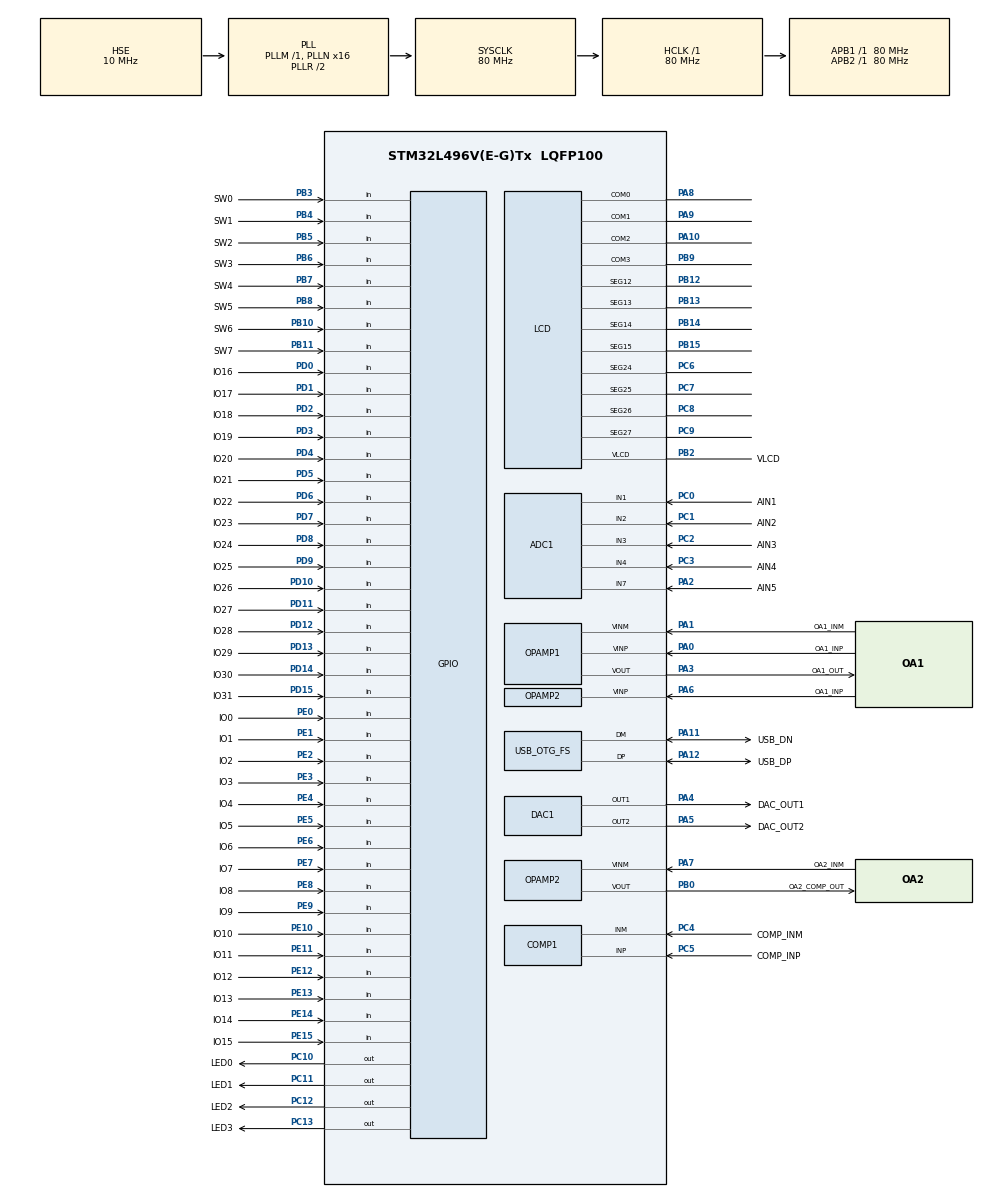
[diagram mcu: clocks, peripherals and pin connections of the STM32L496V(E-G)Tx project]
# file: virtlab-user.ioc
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ADC1.Channel-0\#ChannelRegularConversion=ADC_CHANNEL_1
ADC1.ClockPrescaler=ADC_CLOCK_ASYNC_DIV2
ADC1.NbrOfConversionFlag=1
ADC1.OffsetNumber-0\#ChannelRegularConversion=ADC_OFFSET_NONE
ADC1.Rank-0\#ChannelRegularConversion=1
ADC1.SamplingTime-0\#ChannelRegularConversion=ADC_SAMPLETIME_2CYCLES_5
ADC1.master=1
ADC3.Channel-1\#ChannelRegularConversion=ADC_CHANNEL_14
ADC3.ClockPrescaler=ADC_CLOCK_ASYNC_DIV2
ADC3.NbrOfConversionFlag=1
ADC3.OffsetNumber-1\#ChannelRegularConversion=ADC_OFFSET_NONE
ADC3.Rank-1\#ChannelRegularConversion=1
ADC3.SamplingTime-1\#ChannelRegularConversion=ADC_SAMPLETIME_2CYCLES_5
DAC1.DAC_Channel-DAC_OUT2_ExtAndInt=DAC_CHANNEL_2
DAC1.DAC_UserTrimming-DAC_OUT1_ExtAndInt=DAC_TRIMMING_FACTORY
FREERTOS.BinarySemaphores01=myBinarySem,Dynamic,NULL
FREERTOS.Mutexes01=myMutex,Dynamic,NULL
FREERTOS.Tasks01=defaultTask,24,1024,StartDefaultTask,As weak,NULL,Static,defaultTaskBuffer,defaultTaskControlBlock;usbTxTask,24,1024,StartUsbTxTask,As external,NULL,Static,usbTxTaskBuffer,usbTxTaskControlBlock;myTask1,24,128,StartTask1,Default,NULL,Dynamic,NULL,NULL;myTask2,24,128,StartTask2,Default,NULL,Dynamic,NULL,NULL;myTask3,24,128,StartTask3,Default,NULL,Dynamic,NULL,NULL
FREERTOS.configUSE_NEWLIB_REENTRANT=1
Mcu.Family=STM32L4
Mcu.Name=STM32L496V(E-G)Tx
Mcu.Package=LQFP100
NVIC.OTG_FS_IRQn=true\:5\:0\:false\:false\:true\:false\:false\:true\:true
NVIC.PriorityGroup=NVIC_PRIORITYGROUP_4
NVIC.TIM1_UP_TIM16_IRQn=true\:0\:0\:false\:false\:true\:false\:false\:true\:true
NVIC.TimeBase=TIM1_UP_TIM16_IRQn
NVIC.TimeBaseIP=TIM16
OPAMP2.PowerSupplyRange=OPAMP_POWERSUPPLY_LOW
PA0.GPIO_Label=OA1_INP
PA0.Mode=PGA Connected
PA0.Signal=OPAMP1_VINP
PA1.GPIO_Label=OA1_INM
PA1.Mode=PGA Connected
PA1.Signal=OPAMP1_VINM
PA10.Mode=1/4 Duty Cycle
PA10.Signal=LCD_COM2
PA11.GPIO_Label=USB_DN
PA11.Mode=Device_Only
PA11.Signal=USB_OTG_FS_DM
PA12.GPIO_Label=USB_DP
PA12.Mode=Device_Only
PA12.Signal=USB_OTG_FS_DP
PA13\ (JTMS/SWDIO).GPIO_Label=SWDIO
PA13\ (JTMS/SWDIO).Mode=Serial_Wire
PA13\ (JTMS/SWDIO).Signal=SYS_JTMS-SWDIO
PA14\ (JTCK/SWCLK).GPIO_Label=SWCLK
PA14\ (JTCK/SWCLK).Mode=Serial_Wire
PA14\ (JTCK/SWCLK).Signal=SYS_JTCK-SWCLK
PA2.GPIO_Label=AIN5
PA2.Signal=ADCx_IN7
PA3.GPIO_Label=OA1_OUT
PA3.Mode=PGA Connected
PA3.Signal=OPAMP1_VOUT
PA4.GPIO_Label=DAC_OUT1
PA4.Signal=COMP_DAC11_group
PA5.GPIO_Label=DAC_OUT2
PA5.Signal=COMP_DAC12_group
PA6.GPIO_Label=OA1_INP
PA6.Mode=PGA Connected
PA6.Signal=OPAMP2_VINP
PA7.GPIO_Label=OA2_INM
PA7.Mode=PGA Connected
PA7.Signal=OPAMP2_VINM
PA8.Mode=1/4 Duty Cycle
PA8.Signal=LCD_COM0
PA9.Mode=1/4 Duty Cycle
PA9.Signal=LCD_COM1
PB0.GPIO_Label=OA2_COMP_OUT
PB0.Mode=PGA Connected
PB0.Signal=OPAMP2_VOUT
PB10.GPIO_Label=SW6
PB10.GPIO_PuPd=GPIO_PULLDOWN
PB10.Signal=GPIO_Input
PB11.GPIO_Label=SW7
PB11.GPIO_PuPd=GPIO_PULLDOWN
PB11.Signal=GPIO_Input
PB12.Mode=SEG12
PB12.Signal=LCD_SEG12
PB13.Mode=SEG13
PB13.Signal=LCD_SEG13
PB14.Mode=SEG14
PB14.Signal=LCD_SEG14
PB15.Mode=SEG15
PB15.Signal=LCD_SEG15
PB2.GPIO_Label=VLCD
PB2.Mode=1/4 Duty Cycle
PB2.Signal=LCD_VLCD
PB3\ (JTDO/TRACESWO).GPIO_Label=SW0
PB3\ (JTDO/TRACESWO).GPIO_PuPd=GPIO_PULLDOWN
PB3\ (JTDO/TRACESWO).Signal=GPIO_Input
PB4\ (NJTRST).GPIO_Label=SW1
PB4\ (NJTRST).GPIO_PuPd=GPIO_PULLDOWN
PB4\ (NJTRST).Signal=GPIO_Input
PB5.GPIO_Label=SW2
PB5.GPIO_PuPd=GPIO_PULLDOWN
PB5.Signal=GPIO_Input
PB6.GPIO_Label=SW3
PB6.GPIO_PuPd=GPIO_PULLDOWN
PB6.Signal=GPIO_Input
PB7.GPIO_Label=SW4
PB7.GPIO_PuPd=GPIO_PULLDOWN
PB7.Signal=GPIO_Input
PB8.GPIO_Label=SW5
PB8.GPIO_PuPd=GPIO_PULLDOWN
PB8.Signal=GPIO_Input
PB9.Mode=1/4 Duty Cycle
PB9.Signal=LCD_COM3
PC0.GPIO_Label=AIN1
PC0.Signal=ADCx_IN1
PC1.GPIO_Label=AIN2
PC1.Signal=ADCx_IN2
PC10.GPIO_Label=LED0
PC10.Signal=GPIO_Output
PC11.GPIO_Label=LED1
PC11.Signal=GPIO_Output
PC12.GPIO_Label=LED2
PC12.Signal=GPIO_Output
PC13.GPIO_Label=LED3
PC13.Signal=GPIO_Output
PC14-OSC32_IN\ (PC14).GPIO_Label=OSC32_IN
PC14-OSC32_IN\ (PC14).Mode=LSE-External-Clock-Source
PC14-OSC32_IN\ (PC14).Signal=RCC_OSC32_IN
PC2.GPIO_Label=AIN3
PC2.Signal=ADCx_IN3
PC3.GPIO_Label=AIN4
PC3.Signal=ADCx_IN4
PC4.GPIO_Label=COMP_INM
PC4.Mode=INM
PC4.Signal=COMP1_INM
PC5.GPIO_Label=COMP_INP
PC5.Mode=INP
PC5.Signal=COMP1_INP
PC6.Mode=SEG24
PC6.Signal=LCD_SEG24
PC7.Mode=SEG25
PC7.Signal=LCD_SEG25
PC8.Mode=SEG26
PC8.Signal=LCD_SEG26
PC9.Mode=SEG27
PC9.Signal=LCD_SEG27
PD0.GPIO_Label=IO16
PD0.Signal=GPIO_Input
PD1.GPIO_Label=IO17
PD1.Signal=GPIO_Input
PD10.GPIO_Label=IO26
PD10.Signal=GPIO_Input
PD11.GPIO_Label=IO27
PD11.Signal=GPIO_Input
PD12.GPIO_Label=IO28
PD12.Signal=GPIO_Input
PD13.GPIO_Label=IO29
PD13.Signal=GPIO_Input
PD14.GPIO_Label=IO30
PD14.Signal=GPIO_Input
PD15.GPIO_Label=IO31
PD15.Signal=GPIO_Input
PD2.GPIO_Label=IO18
PD2.Signal=GPIO_Input
PD3.GPIO_Label=IO19
PD3.Signal=GPIO_Input
PD4.GPIO_Label=IO20
PD4.Signal=GPIO_Input
PD5.GPIO_Label=IO21
PD5.Signal=GPIO_Input
PD6.GPIO_Label=IO22
PD6.Signal=GPIO_Input
PD7.GPIO_Label=IO23
PD7.Signal=GPIO_Input
PD8.GPIO_Label=IO24
PD8.Signal=GPIO_Input
PD9.GPIO_Label=IO25
PD9.Signal=GPIO_Input
PE0.GPIO_Label=IO0
PE0.Signal=GPIO_Input
PE1.GPIO_Label=IO1
PE1.Signal=GPIO_Input
PE10.GPIO_Label=IO10
PE10.Signal=GPIO_Input
PE11.GPIO_Label=IO11
PE11.Signal=GPIO_Input
PE12.GPIO_Label=IO12
PE12.Signal=GPIO_Input
PE13.GPIO_Label=IO13
PE13.Signal=GPIO_Input
PE14.GPIO_Label=IO14
PE14.Signal=GPIO_Input
PE15.GPIO_Label=IO15
PE15.GPIO_PuPd=GPIO_PULLUP
PE15.Signal=GPIO_Input
PE2.GPIO_Label=IO2
PE2.Signal=GPIO_Input
PE3.GPIO_Label=IO3
PE3.Signal=GPIO_Input
PE4.GPIO_Label=IO4
PE4.Signal=GPIO_Input
PE5.GPIO_Label=IO5
PE5.Signal=GPIO_Input
PE6.GPIO_Label=IO6
PE6.Signal=GPIO_Input
PE7.GPIO_Label=IO7
PE7.Signal=GPIO_Input
PE8.GPIO_Label=IO8
PE8.Signal=GPIO_Input
PE9.GPIO_Label=IO9
PE9.Signal=GPIO_Input
PH0-OSC_IN\ (PH0).GPIO_Label=OSC_IN
PH0-OSC_IN\ (PH0).Mode=HSE-External-Clock-Source
PH0-OSC_IN\ (PH0).Signal=RCC_OSC_IN
ProjectManager.HeapSize=0x200
ProjectManager.StackSize=0x400
ProjectManager.TargetToolchain=STM32CubeIDE
RCC.ADCFreq_Value=80000000
RCC.AHBFreq_Value=80000000
RCC.APB1Freq_Value=80000000
RCC.APB1TimFreq_Value=80000000
RCC.APB2Freq_Value=80000000
RCC.APB2TimFreq_Value=80000000
RCC.CK48CLockSelection=RCC_USBCLKSOURCE_HSI48
RCC.CortexFreq_Value=80000000
RCC.HCLKFreq_Value=80000000
RCC.HSE_VALUE=10000000
RCC.HSI48_VALUE=48000000
RCC.HSI_VALUE=16000000
RCC.LSCOSource1=RCC_LSCOSOURCE_LSE
RCC.LSE_VALUE=32768
RCC.MSI_VALUE=4000000
RCC.PLLN=16
RCC.PLLSAI1N=32
RCC.PLLSAI1Q=RCC_PLLQ_DIV4
RCC.PLLSAI1R=RCC_PLLR_DIV4
RCC.PLLSAI2N=10
RCC.PLLSourceVirtual=RCC_PLLSOURCE_HSE
RCC.RCC_MCODiv=RCC_MCODIV_8
RCC.RTCClockSelection=RCC_RTCCLKSOURCE_LSE
RCC.SYSCLKFreq_VALUE=80000000
RCC.SYSCLKSource=RCC_SYSCLKSOURCE_PLLCLK
RCC.USBFreq_Value=48000000
RCC.VCOOutputFreq_Value=160000000
SH.ADCx_IN1.0=ADC1_IN1,IN1-Single-Ended
SH.ADCx_IN2.0=ADC1_IN2,IN2-Single-Ended
SH.ADCx_IN3.0=ADC1_IN3,IN3-Single-Ended
SH.ADCx_IN4.0=ADC1_IN4,IN4-Single-Ended
SH.ADCx_IN7.0=ADC1_IN7,IN7-Single-Ended
SH.COMP_DAC11_group.0=DAC1_OUT1,DAC_OUT1_ExtAndInt
SH.COMP_DAC12_group.0=DAC1_OUT2,DAC_OUT2_ExtAndInt
SYS.VoltageScaling=SYSCFG_VREFBUF_VOLTAGE_SCALE0
USB_DEVICE.CLASS_NAME_FS=CDC
USB_DEVICE.MANUFACTURER_STRING=MRR
USB_DEVICE.PID_CDC_FS=0x5740
USB_DEVICE.PRODUCT_STRING_CDC_FS=VL User ComPort
USB_DEVICE.USBD_LPM_ENABLED=0
USB_DEVICE.USBD_SELF_POWERED=0
USB_DEVICE.VID=0x483
USB_DEVICE.VirtualMode=Cdc
USB_DEVICE.VirtualModeFS=Cdc_FS
USB_OTG_FS.VirtualMode=Device_Only
VP_ADC1_OPAMP1_OUT.Mode=IN8-OPAMP1-Single-Ended
VP_ADC1_OPAMP2_OUT.Mode=IN15-OPAMP2-Single-Ended
VP_ADC3_VS_DAC1_OUT1_L4.Mode=IN-DAC1-OUT1
VP_ADC3_VS_DAC1_OUT2_L4.Mode=IN-DAC1-OUT2
VP_FREERTOS_VS_CMSIS_V2.Mode=CMSIS_V2
VP_SYS_VS_tim16.Mode=TIM16
VP_USB_DEVICE_VS_USB_DEVICE_CDC_FS.Mode=CDC_FS
VREF+.Mode=InternalMode
VREF+.Signal=VREFBUF_OUT
board=custom

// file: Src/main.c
/* USER CODE BEGIN Header */
/**
  ******************************************************************************
  * @file           : main.c
  * @brief          : Main program body
  ******************************************************************************
  * @attention
  *
  * <h2><center>&copy; Copyright (c) 2020 STMicroelectronics.
  * All rights reserved.</center></h2>
  *
  * This software component is licensed by ST under Ultimate Liberty license
  * SLA0044, the "License"; You may not use this file except in compliance with
  * the License. You may obtain a copy of the License at:
  *                             www.st.com/SLA0044
  *
  ******************************************************************************
  */
/* USER CODE END Header */
#include "main.h"
#include "cmsis_os.h"
#include "usb_device.h"

/* USER CODE BEGIN Includes */
#include "usbserial.h"
/* USER CODE END Includes */

typedef StaticTask_t osStaticThreadDef_t;

ADC_HandleTypeDef hadc1;
ADC_HandleTypeDef hadc3;

COMP_HandleTypeDef hcomp1;

DAC_HandleTypeDef hdac1;

LCD_HandleTypeDef hlcd;

OPAMP_HandleTypeDef hopamp1;
OPAMP_HandleTypeDef hopamp2;

/* Definitions for defaultTask */
osThreadId_t defaultTaskHandle;
uint32_t defaultTaskBuffer[ 1024 ];
osStaticThreadDef_t defaultTaskControlBlock;
const osThreadAttr_t defaultTask_attributes = {
  .name = "defaultTask",
  .cb_mem = &defaultTaskControlBlock,
  .cb_size = sizeof(defaultTaskControlBlock),
  .stack_mem = &defaultTaskBuffer[0],
  .stack_size = sizeof(defaultTaskBuffer),
  .priority = (osPriority_t) osPriorityNormal,
};
/* Definitions for usbTxTask */
osThreadId_t usbTxTaskHandle;
uint32_t usbTxTaskBuffer[ 1024 ];
osStaticThreadDef_t usbTxTaskControlBlock;
const osThreadAttr_t usbTxTask_attributes = {
  .name = "usbTxTask",
  .cb_mem = &usbTxTaskControlBlock,
  .cb_size = sizeof(usbTxTaskControlBlock),
  .stack_mem = &usbTxTaskBuffer[0],
  .stack_size = sizeof(usbTxTaskBuffer),
  .priority = (osPriority_t) osPriorityNormal,
};
/* Definitions for myTask1 */
osThreadId_t myTask1Handle;
const osThreadAttr_t myTask1_attributes = {
  .name = "myTask1",
  .stack_size = 128 * 4,
  .priority = (osPriority_t) osPriorityNormal,
};
/* Definitions for myTask2 */
osThreadId_t myTask2Handle;
const osThreadAttr_t myTask2_attributes = {
  .name = "myTask2",
  .stack_size = 128 * 4,
  .priority = (osPriority_t) osPriorityNormal,
};
/* Definitions for myTask3 */
osThreadId_t myTask3Handle;
const osThreadAttr_t myTask3_attributes = {
  .name = "myTask3",
  .stack_size = 128 * 4,
  .priority = (osPriority_t) osPriorityNormal,
};
/* Definitions for myMutex */
osMutexId_t myMutexHandle;
const osMutexAttr_t myMutex_attributes = {
  .name = "myMutex"
};
/* Definitions for myBinarySem */
osSemaphoreId_t myBinarySemHandle;
const osSemaphoreAttr_t myBinarySem_attributes = {
  .name = "myBinarySem"
};

void SystemClock_Config(void);
void PeriphCommonClock_Config(void);
static void MX_GPIO_Init(void);
static void MX_DAC1_Init(void);
static void MX_OPAMP1_Init(void);
static void MX_OPAMP2_Init(void);
static void MX_ADC1_Init(void);
static void MX_ADC3_Init(void);
static void MX_COMP1_Init(void);
static void MX_LCD_Init(void);
void StartDefaultTask(void *argument);
extern void StartUsbTxTask(void *argument);
void StartTask1(void *argument);
void StartTask2(void *argument);
void StartTask3(void *argument);

int main(void)
{

  /* MCU Configuration--------------------------------------------------------*/

  /* Reset of all peripherals, Initializes the Flash interface and the Systick. */
  HAL_Init();

  /* Configure the system clock */
  SystemClock_Config();

/* Configure the peripherals common clocks */
  PeriphCommonClock_Config();

  /* Initialize all configured peripherals */
  MX_GPIO_Init();
  MX_DAC1_Init();
  MX_OPAMP1_Init();
  MX_OPAMP2_Init();
  MX_ADC1_Init();
  MX_ADC3_Init();
  MX_COMP1_Init();
  MX_LCD_Init();

  /* Init scheduler */
  osKernelInitialize();
  /* Create the mutex(es) */
  /* creation of myMutex */
  myMutexHandle = osMutexNew(&myMutex_attributes);

  /* Create the semaphores(s) */
  /* creation of myBinarySem */
  myBinarySemHandle = osSemaphoreNew(1, 1, &myBinarySem_attributes);

  /* Create the thread(s) */
  /* creation of defaultTask */
  defaultTaskHandle = osThreadNew(StartDefaultTask, NULL, &defaultTask_attributes);

  /* creation of usbTxTask */
  usbTxTaskHandle = osThreadNew(StartUsbTxTask, NULL, &usbTxTask_attributes);

  /* creation of myTask1 */
  myTask1Handle = osThreadNew(StartTask1, NULL, &myTask1_attributes);

  /* creation of myTask2 */
  myTask2Handle = osThreadNew(StartTask2, NULL, &myTask2_attributes);

  /* creation of myTask3 */
  myTask3Handle = osThreadNew(StartTask3, NULL, &myTask3_attributes);

  /* Start scheduler */
  osKernelStart();

  /* We should never get here as control is now taken by the scheduler */
  /* Infinite loop */
  while (1)
  {

  }
}

void SystemClock_Config(void)
{
  RCC_OscInitTypeDef RCC_OscInitStruct = {0};
  RCC_ClkInitTypeDef RCC_ClkInitStruct = {0};

  /** Configure the main internal regulator output voltage
  */
  if (HAL_PWREx_ControlVoltageScaling(PWR_REGULATOR_VOLTAGE_SCALE1) != HAL_OK)
  {
    Error_Handler();
  }

  /** Initializes the RCC Oscillators according to the specified parameters
  * in the RCC_OscInitTypeDef structure.
  */
  RCC_OscInitStruct.OscillatorType = RCC_OSCILLATORTYPE_HSI48|RCC_OSCILLATORTYPE_HSE
                              |RCC_OSCILLATORTYPE_LSE;
  RCC_OscInitStruct.HSEState = RCC_HSE_BYPASS;
  RCC_OscInitStruct.LSEState = RCC_LSE_BYPASS;
  RCC_OscInitStruct.HSI48State = RCC_HSI48_ON;
  RCC_OscInitStruct.PLL.PLLState = RCC_PLL_ON;
  RCC_OscInitStruct.PLL.PLLSource = RCC_PLLSOURCE_HSE;
  RCC_OscInitStruct.PLL.PLLM = 1;
  RCC_OscInitStruct.PLL.PLLN = 16;
  RCC_OscInitStruct.PLL.PLLP = RCC_PLLP_DIV2;
  RCC_OscInitStruct.PLL.PLLQ = RCC_PLLQ_DIV2;
  RCC_OscInitStruct.PLL.PLLR = RCC_PLLR_DIV2;
  if (HAL_RCC_OscConfig(&RCC_OscInitStruct) != HAL_OK)
  {
    Error_Handler();
  }

  /** Initializes the CPU, AHB and APB buses clocks
  */
  RCC_ClkInitStruct.ClockType = RCC_CLOCKTYPE_HCLK|RCC_CLOCKTYPE_SYSCLK
                              |RCC_CLOCKTYPE_PCLK1|RCC_CLOCKTYPE_PCLK2;
  RCC_ClkInitStruct.SYSCLKSource = RCC_SYSCLKSOURCE_PLLCLK;
  RCC_ClkInitStruct.AHBCLKDivider = RCC_SYSCLK_DIV1;
  RCC_ClkInitStruct.APB1CLKDivider = RCC_HCLK_DIV1;
  RCC_ClkInitStruct.APB2CLKDivider = RCC_HCLK_DIV1;

  if (HAL_RCC_ClockConfig(&RCC_ClkInitStruct, FLASH_LATENCY_4) != HAL_OK)
  {
    Error_Handler();
  }
}

void PeriphCommonClock_Config(void)
{
  RCC_PeriphCLKInitTypeDef PeriphClkInit = {0};

  /** Initializes the peripherals clock
  */
  PeriphClkInit.PeriphClockSelection = RCC_PERIPHCLK_ADC;
  PeriphClkInit.AdcClockSelection = RCC_ADCCLKSOURCE_PLLSAI1;
  PeriphClkInit.PLLSAI1.PLLSAI1Source = RCC_PLLSOURCE_HSE;
  PeriphClkInit.PLLSAI1.PLLSAI1M = 1;
  PeriphClkInit.PLLSAI1.PLLSAI1N = 32;
  PeriphClkInit.PLLSAI1.PLLSAI1P = RCC_PLLP_DIV2;
  PeriphClkInit.PLLSAI1.PLLSAI1Q = RCC_PLLQ_DIV4;
  PeriphClkInit.PLLSAI1.PLLSAI1R = RCC_PLLR_DIV4;
  PeriphClkInit.PLLSAI1.PLLSAI1ClockOut = RCC_PLLSAI1_ADC1CLK;
  if (HAL_RCCEx_PeriphCLKConfig(&PeriphClkInit) != HAL_OK)
  {
    Error_Handler();
  }
}

static void MX_ADC1_Init(void)
{

  ADC_MultiModeTypeDef multimode = {0};
  ADC_ChannelConfTypeDef sConfig = {0};

  /** Common config
  */
  hadc1.Instance = ADC1;
  hadc1.Init.ClockPrescaler = ADC_CLOCK_ASYNC_DIV2;
  hadc1.Init.Resolution = ADC_RESOLUTION_12B;
  hadc1.Init.DataAlign = ADC_DATAALIGN_RIGHT;
  hadc1.Init.ScanConvMode = ADC_SCAN_DISABLE;
  hadc1.Init.EOCSelection = ADC_EOC_SINGLE_CONV;
  hadc1.Init.LowPowerAutoWait = DISABLE;
  hadc1.Init.ContinuousConvMode = DISABLE;
  hadc1.Init.NbrOfConversion = 1;
  hadc1.Init.DiscontinuousConvMode = DISABLE;
  hadc1.Init.ExternalTrigConv = ADC_SOFTWARE_START;
  hadc1.Init.ExternalTrigConvEdge = ADC_EXTERNALTRIGCONVEDGE_NONE;
  hadc1.Init.DMAContinuousRequests = DISABLE;
  hadc1.Init.Overrun = ADC_OVR_DATA_PRESERVED;
  hadc1.Init.OversamplingMode = DISABLE;
  if (HAL_ADC_Init(&hadc1) != HAL_OK)
  {
    Error_Handler();
  }

  /** Configure the ADC multi-mode
  */
  multimode.Mode = ADC_MODE_INDEPENDENT;
  if (HAL_ADCEx_MultiModeConfigChannel(&hadc1, &multimode) != HAL_OK)
  {
    Error_Handler();
  }

  /** Configure Regular Channel
  */
  sConfig.Channel = ADC_CHANNEL_1;
  sConfig.Rank = ADC_REGULAR_RANK_1;
  sConfig.SamplingTime = ADC_SAMPLETIME_2CYCLES_5;
  sConfig.SingleDiff = ADC_SINGLE_ENDED;
  sConfig.OffsetNumber = ADC_OFFSET_NONE;
  sConfig.Offset = 0;
  if (HAL_ADC_ConfigChannel(&hadc1, &sConfig) != HAL_OK)
  {
    Error_Handler();
  }

}

static void MX_ADC3_Init(void)
{

  ADC_ChannelConfTypeDef sConfig = {0};

  /** Common config
  */
  hadc3.Instance = ADC3;
  hadc3.Init.ClockPrescaler = ADC_CLOCK_ASYNC_DIV2;
  hadc3.Init.Resolution = ADC_RESOLUTION_12B;
  hadc3.Init.DataAlign = ADC_DATAALIGN_RIGHT;
  hadc3.Init.ScanConvMode = ADC_SCAN_DISABLE;
  hadc3.Init.EOCSelection = ADC_EOC_SINGLE_CONV;
  hadc3.Init.LowPowerAutoWait = DISABLE;
  hadc3.Init.ContinuousConvMode = DISABLE;
  hadc3.Init.NbrOfConversion = 1;
  hadc3.Init.DiscontinuousConvMode = DISABLE;
  hadc3.Init.ExternalTrigConv = ADC_SOFTWARE_START;
  hadc3.Init.ExternalTrigConvEdge = ADC_EXTERNALTRIGCONVEDGE_NONE;
  hadc3.Init.DMAContinuousRequests = DISABLE;
  hadc3.Init.Overrun = ADC_OVR_DATA_PRESERVED;
  hadc3.Init.OversamplingMode = DISABLE;
  if (HAL_ADC_Init(&hadc3) != HAL_OK)
  {
    Error_Handler();
  }

  /** Configure Regular Channel
  */
  sConfig.Channel = ADC_CHANNEL_14;
  sConfig.Rank = ADC_REGULAR_RANK_1;
  sConfig.SamplingTime = ADC_SAMPLETIME_2CYCLES_5;
  sConfig.SingleDiff = ADC_SINGLE_ENDED;
  sConfig.OffsetNumber = ADC_OFFSET_NONE;
  sConfig.Offset = 0;
  if (HAL_ADC_ConfigChannel(&hadc3, &sConfig) != HAL_OK)
  {
    Error_Handler();
  }

}

static void MX_COMP1_Init(void)
{

  hcomp1.Instance = COMP1;
  hcomp1.Init.InvertingInput = COMP_INPUT_MINUS_IO2;
  hcomp1.Init.NonInvertingInput = COMP_INPUT_PLUS_IO1;
  hcomp1.Init.OutputPol = COMP_OUTPUTPOL_NONINVERTED;
  hcomp1.Init.Hysteresis = COMP_HYSTERESIS_NONE;
  hcomp1.Init.BlankingSrce = COMP_BLANKINGSRC_NONE;
  hcomp1.Init.Mode = COMP_POWERMODE_HIGHSPEED;
  hcomp1.Init.WindowMode = COMP_WINDOWMODE_DISABLE;
  hcomp1.Init.TriggerMode = COMP_TRIGGERMODE_NONE;
  if (HAL_COMP_Init(&hcomp1) != HAL_OK)
  {
    Error_Handler();
  }

}

static void MX_DAC1_Init(void)
{

  DAC_ChannelConfTypeDef sConfig = {0};

  /** DAC Initialization
  */
  hdac1.Instance = DAC1;
  if (HAL_DAC_Init(&hdac1) != HAL_OK)
  {
    Error_Handler();
  }

  /** DAC channel OUT1 config
  */
  sConfig.DAC_SampleAndHold = DAC_SAMPLEANDHOLD_DISABLE;
  sConfig.DAC_Trigger = DAC_TRIGGER_NONE;
  sConfig.DAC_OutputBuffer = DAC_OUTPUTBUFFER_ENABLE;
  sConfig.DAC_ConnectOnChipPeripheral = DAC_CHIPCONNECT_ENABLE;
  sConfig.DAC_UserTrimming = DAC_TRIMMING_FACTORY;
  if (HAL_DAC_ConfigChannel(&hdac1, &sConfig, DAC_CHANNEL_1) != HAL_OK)
  {
    Error_Handler();
  }

  /** DAC channel OUT2 config
  */
  if (HAL_DAC_ConfigChannel(&hdac1, &sConfig, DAC_CHANNEL_2) != HAL_OK)
  {
    Error_Handler();
  }

}

static void MX_LCD_Init(void)
{

  hlcd.Instance = LCD;
  hlcd.Init.Prescaler = LCD_PRESCALER_1;
  hlcd.Init.Divider = LCD_DIVIDER_16;
  hlcd.Init.Duty = LCD_DUTY_1_4;
  hlcd.Init.Bias = LCD_BIAS_1_4;
  hlcd.Init.VoltageSource = LCD_VOLTAGESOURCE_INTERNAL;
  hlcd.Init.Contrast = LCD_CONTRASTLEVEL_0;
  hlcd.Init.DeadTime = LCD_DEADTIME_0;
  hlcd.Init.PulseOnDuration = LCD_PULSEONDURATION_0;
  hlcd.Init.MuxSegment = LCD_MUXSEGMENT_DISABLE;
  hlcd.Init.BlinkMode = LCD_BLINKMODE_OFF;
  hlcd.Init.BlinkFrequency = LCD_BLINKFREQUENCY_DIV8;
  hlcd.Init.HighDrive = LCD_HIGHDRIVE_DISABLE;
  if (HAL_LCD_Init(&hlcd) != HAL_OK)
  {
    Error_Handler();
  }

}

static void MX_OPAMP1_Init(void)
{

  hopamp1.Instance = OPAMP1;
  hopamp1.Init.PowerSupplyRange = OPAMP_POWERSUPPLY_LOW;
  hopamp1.Init.Mode = OPAMP_PGA_MODE;
  hopamp1.Init.NonInvertingInput = OPAMP_NONINVERTINGINPUT_IO0;
  hopamp1.Init.InvertingInput = OPAMP_INVERTINGINPUT_IO0;
  hopamp1.Init.PgaGain = OPAMP_PGA_GAIN_2;
  hopamp1.Init.PowerMode = OPAMP_POWERMODE_NORMALPOWER;
  hopamp1.Init.UserTrimming = OPAMP_TRIMMING_FACTORY;
  if (HAL_OPAMP_Init(&hopamp1) != HAL_OK)
  {
    Error_Handler();
  }

}

static void MX_OPAMP2_Init(void)
{

  hopamp2.Instance = OPAMP2;
  hopamp2.Init.PowerSupplyRange = OPAMP_POWERSUPPLY_LOW;
  hopamp2.Init.Mode = OPAMP_PGA_MODE;
  hopamp2.Init.NonInvertingInput = OPAMP_NONINVERTINGINPUT_IO0;
  hopamp2.Init.InvertingInput = OPAMP_INVERTINGINPUT_IO0;
  hopamp2.Init.PgaGain = OPAMP_PGA_GAIN_2;
  hopamp2.Init.PowerMode = OPAMP_POWERMODE_NORMALPOWER;
  hopamp2.Init.UserTrimming = OPAMP_TRIMMING_FACTORY;
  if (HAL_OPAMP_Init(&hopamp2) != HAL_OK)
  {
    Error_Handler();
  }

}

static void MX_GPIO_Init(void)
{
  LL_GPIO_InitTypeDef GPIO_InitStruct = {0};

  /* GPIO Ports Clock Enable */
  LL_AHB2_GRP1_EnableClock(LL_AHB2_GRP1_PERIPH_GPIOE);
  LL_AHB2_GRP1_EnableClock(LL_AHB2_GRP1_PERIPH_GPIOC);
  LL_AHB2_GRP1_EnableClock(LL_AHB2_GRP1_PERIPH_GPIOH);
  LL_AHB2_GRP1_EnableClock(LL_AHB2_GRP1_PERIPH_GPIOA);
  LL_AHB2_GRP1_EnableClock(LL_AHB2_GRP1_PERIPH_GPIOB);
  LL_AHB2_GRP1_EnableClock(LL_AHB2_GRP1_PERIPH_GPIOD);

  /**/
  LL_GPIO_ResetOutputPin(GPIOC, LED3_Pin|LED0_Pin|LED1_Pin|LED2_Pin);

  /**/
  GPIO_InitStruct.Pin = IO2_Pin|IO3_Pin|IO4_Pin|IO5_Pin
                          |IO6_Pin|IO7_Pin|IO8_Pin|IO9_Pin
                          |IO10_Pin|IO11_Pin|IO12_Pin|IO13_Pin
                          |IO14_Pin|IO0_Pin|IO1_Pin;
  GPIO_InitStruct.Mode = LL_GPIO_MODE_INPUT;
  GPIO_InitStruct.Pull = LL_GPIO_PULL_NO;
  LL_GPIO_Init(GPIOE, &GPIO_InitStruct);

  /**/
  GPIO_InitStruct.Pin = LED3_Pin|LED0_Pin|LED1_Pin|LED2_Pin;
  GPIO_InitStruct.Mode = LL_GPIO_MODE_OUTPUT;
  GPIO_InitStruct.Speed = LL_GPIO_SPEED_FREQ_LOW;
  GPIO_InitStruct.OutputType = LL_GPIO_OUTPUT_PUSHPULL;
  GPIO_InitStruct.Pull = LL_GPIO_PULL_NO;
  LL_GPIO_Init(GPIOC, &GPIO_InitStruct);

  /**/
  GPIO_InitStruct.Pin = LL_GPIO_PIN_15;
  GPIO_InitStruct.Mode = LL_GPIO_MODE_ANALOG;
  GPIO_InitStruct.Pull = LL_GPIO_PULL_NO;
  LL_GPIO_Init(GPIOC, &GPIO_InitStruct);

  /**/
  GPIO_InitStruct.Pin = LL_GPIO_PIN_1|LL_GPIO_PIN_3;
  GPIO_InitStruct.Mode = LL_GPIO_MODE_ANALOG;
  GPIO_InitStruct.Pull = LL_GPIO_PULL_NO;
  LL_GPIO_Init(GPIOH, &GPIO_InitStruct);

  /**/
  GPIO_InitStruct.Pin = LL_GPIO_PIN_1;
  GPIO_InitStruct.Mode = LL_GPIO_MODE_ANALOG;
  GPIO_InitStruct.Pull = LL_GPIO_PULL_NO;
  LL_GPIO_Init(GPIOB, &GPIO_InitStruct);

  /**/
  GPIO_InitStruct.Pin = IO15_Pin;
  GPIO_InitStruct.Mode = LL_GPIO_MODE_INPUT;
  GPIO_InitStruct.Pull = LL_GPIO_PULL_UP;
  LL_GPIO_Init(IO15_GPIO_Port, &GPIO_InitStruct);

  /**/
  GPIO_InitStruct.Pin = SW6_Pin|SW7_Pin|SW0_Pin|SW1_Pin
                          |SW2_Pin|SW3_Pin|SW4_Pin|SW5_Pin;
  GPIO_InitStruct.Mode = LL_GPIO_MODE_INPUT;
  GPIO_InitStruct.Pull = LL_GPIO_PULL_DOWN;
  LL_GPIO_Init(GPIOB, &GPIO_InitStruct);

  /**/
  GPIO_InitStruct.Pin = IO24_Pin|IO25_Pin|IO26_Pin|IO27_Pin
                          |IO28_Pin|IO29_Pin|IO30_Pin|IO31_Pin
                          |IO16_Pin|IO17_Pin|IO18_Pin|IO19_Pin
                          |IO20_Pin|IO21_Pin|IO22_Pin|IO23_Pin;
  GPIO_InitStruct.Mode = LL_GPIO_MODE_INPUT;
  GPIO_InitStruct.Pull = LL_GPIO_PULL_NO;
  LL_GPIO_Init(GPIOD, &GPIO_InitStruct);

  /**/
  GPIO_InitStruct.Pin = LL_GPIO_PIN_15;
  GPIO_InitStruct.Mode = LL_GPIO_MODE_ANALOG;
  GPIO_InitStruct.Pull = LL_GPIO_PULL_NO;
  LL_GPIO_Init(GPIOA, &GPIO_InitStruct);

}

__weak void StartDefaultTask(void *argument)
{
  /* init code for USB_DEVICE */
  //MX_USB_DEVICE_Init();
  for(;;)
  {
    osDelay(1);
  }
}

void StartTask1(void *argument)
{
  /* USER CODE BEGIN StartTask1 */
	//MX_USB_DEVICE_Init();
	int executionCount = 1;  // volte che eseguiamo il codice
  /* Infinite loop */
  for(;;)
  {
	osMutexAcquire(myMutexHandle,osWaitForever); // prendiamo il mutex
	//osSemaphoreAcquire(myBinarySemHandle,osWaitForever); // prendiamo il semaforo

	if (executionCount == 3) { // controlliamo se abbiamo eseguito tre volte il task
		osThreadSetPriority(myTask1Handle, osThreadGetPriority(myTask1Handle) - 1); // abbassiamo la priorità del task di 1
	}

	usbserialPrintf("Task1 executed %d times\r\n", executionCount);

	//LL_GPIO_WriteReg(GPIOC, ODR, LL_GPIO_ReadReg(GPIOC, ODR) ^ (1 << 10)); // usato per controllo senza seriale

	osMutexRelease(myMutexHandle); // rilasciamo il mutex
	//osSemaphoreRelease(myBinarySemHandle); // rlasciamo il semaforo

	HAL_Delay(500); // delay di mezzo secondo

	executionCount++; // aumentiamo il numero di esecuzione del task
  }
  /* USER CODE END StartTask1 */
}

void StartTask2(void *argument)
{
  /* USER CODE BEGIN StartTask2 */
	//MX_USB_DEVICE_Init();
  /* Infinite loop */
  for(;;)
  {
		 osMutexAcquire(myMutexHandle,osWaitForever); // prendiamo il mutex
		 //osSemaphoreAcquire(myBinarySemHandle,osWaitForever); // prendiamo il semaforo

		 usbserialPrint("Task2 executed\r\n");

		 //LL_GPIO_WriteReg(GPIOC, ODR, LL_GPIO_ReadReg(GPIOC, ODR) ^ (1 << 11)); // usato per controllo senza seriale

		 osMutexRelease(myMutexHandle); // rilasciamo il mutex
		 //osSemaphoreRelease(myBinarySemHandle); // rlasciamo il semaforo

		 HAL_Delay(500); // delay di mezzo secondo
  }
  /* USER CODE END StartTask2 */
}

void StartTask3(void *argument)
{
  /* USER CODE BEGIN StartTask3 */
	MX_USB_DEVICE_Init(); // inizializzo l'uscita seriale del lato user
  /* Infinite loop */
  for(;;)
  {
	  	usbserialPrint("Task3 executed\r\n");

	    //LL_GPIO_WriteReg(GPIOC, ODR, LL_GPIO_ReadReg(GPIOC, ODR) ^ (1 << 12)); // usato per controllo senza seriale

	  	HAL_Delay(500); // delay di mezzo secondo
  }
  /* USER CODE END StartTask3 */
}

void HAL_TIM_PeriodElapsedCallback(TIM_HandleTypeDef *htim)
{
  if (htim->Instance == TIM16) {
    HAL_IncTick();
  }
}

void Error_Handler(void)
{
}
